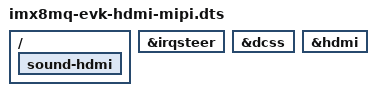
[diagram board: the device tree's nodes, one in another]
// SPDX-License-Identifier: GPL-2.0
/*
 * Copyright 2020 NXP.
 */

#include "imx8mq-evk-lcdif-mipi.dts"

/ {
	sound-hdmi {
		status = "okay";
	};
};

&irqsteer {
	status = "okay";
};

&dcss {
	status = "okay";
};

&hdmi {
	status = "okay";
};
